# ES32F36xx register map
File version: 1.0
Registers are 32-bit, read-write, reset 0x0 unless marked. A register's access mark holds for its fields unless they carry their own. Offsets are from the block's base; [hi:lo] are bit positions; {n}, {i} and the like mark numbered series.

## ADC0
Base 0x40042000
Same registers: ADC1 0x40042400
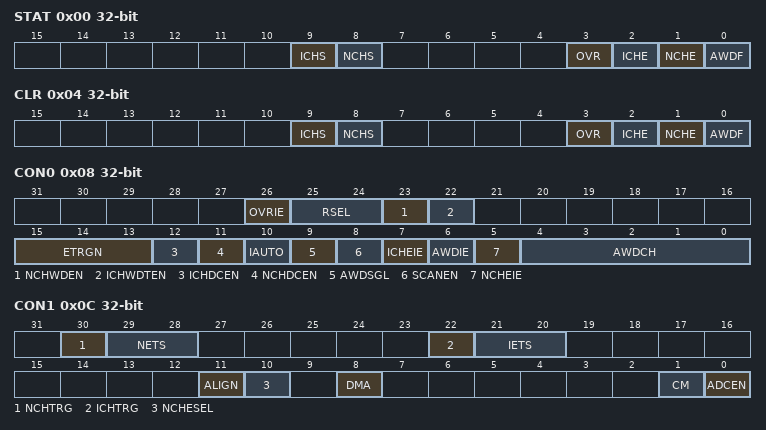
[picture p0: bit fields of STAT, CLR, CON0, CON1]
0x00 STAT read
  [9] ICHS, [8] NCHS, [3] OVR, [2] ICHE, [1] NCHE, [0] AWDF
0x04 CLR write1
  [9] ICHS, [8] NCHS, [3] OVR, [2] ICHE, [1] NCHE, [0] AWDF
0x08 CON0
  [26] OVRIE, [25:24] RSEL, [23] NCHWDEN, [22] ICHWDTEN, [15:13] ETRGN, [12] ICHDCEN, [11] NCHDCEN, [10] IAUTO, [9] AWDSGL, [8] SCANEN, [7] ICHEIE, [6] AWDIE, [5] NCHEIE, [4:0] AWDCH
0x0C CON1
  [30] NCHTRG write1, [29:28] NETS, [22] ICHTRG write1, [21:20] IETS, [11] ALIGN, [10] NCHESEL, [8] DMA, [1] CM, [0] ADCEN
0x10 SMPT1
  [31:0] CHT
0x14 SMPT2
  [31:0] CHT
0x18 SMPT3
  [15:0] CHT
{0x1C+4i} ICHOFF{i} (i=1..4)
  [11:0] IOFF
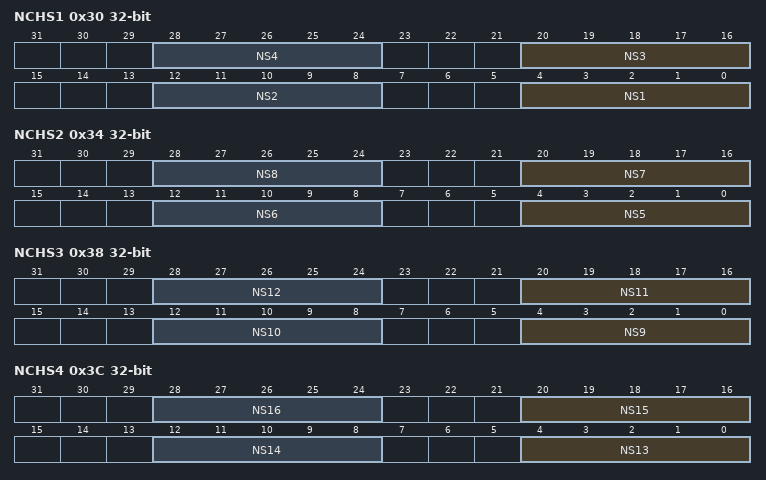
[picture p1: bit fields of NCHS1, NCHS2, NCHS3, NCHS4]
0x30 NCHS1
  [8n-4:8n-8] NS{n} (n=1..4)
0x34 NCHS2
  [8n-36:8n-40] NS{n} (n=5..8)
0x38 NCHS3
  [8n-68:8n-72] NS{n} (n=9..12)
0x3C NCHS4
  [8n-100:8n-104] NS{n} (n=13..16)
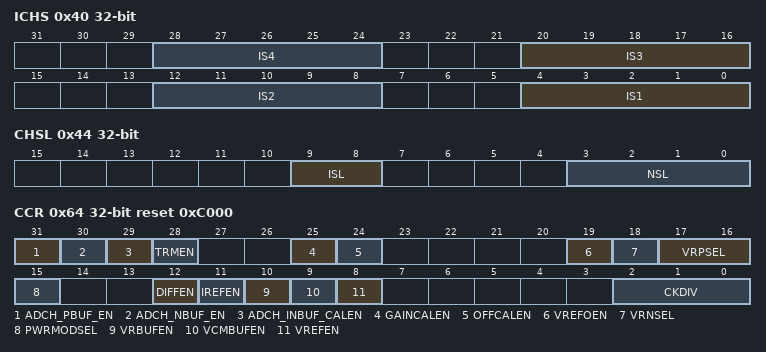
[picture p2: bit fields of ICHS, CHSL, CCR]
0x40 ICHS
  [8n-4:8n-8] IS{n} (n=1..4)
0x44 CHSL
  [9:8] ISL, [3:0] NSL
0x48 WDTH reset 0xFFF
  [11:0] HT
0x4C WDTL
  [11:0] LT
{0x4C+4i} ICHDR{i} read (i=1..4)
  [15:0] VAL
0x60 NCHDR read
  [15:0] VAL
0x64 CCR reset 0xC000
  [31] ADCH_PBUF_EN, [30] ADCH_NBUF_EN, [29] ADCH_INBUF_CALEN, [28] TRMEN, [25] GAINCALEN, [24] OFFCALEN, [19] VREFOEN, [18] VRNSEL, [17:16] VRPSEL, [15] PWRMODSEL, [12] DIFFEN, [11] IREFEN, [10] VRBUFEN, [9] VCMBUFEN, [8] VREFEN, [2:0] CKDIV

## ACMP0
Base 0x40043000
Same registers: ACMP1 0x40043400, ACMP2 0x40043800
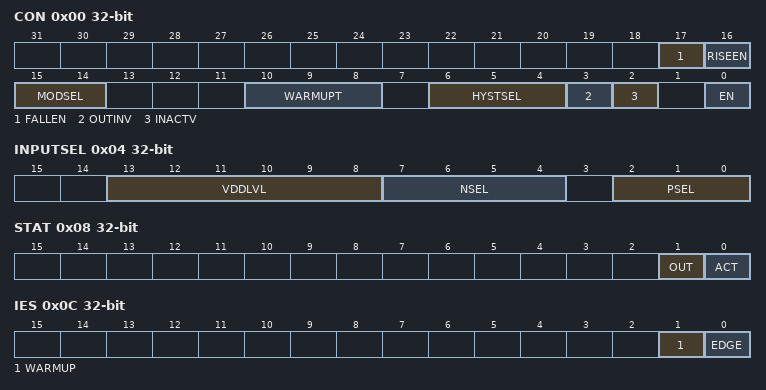
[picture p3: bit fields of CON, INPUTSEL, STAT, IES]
0x00 CON
  [17] FALLEN, [16] RISEEN, [15:14] MODSEL, [10:8] WARMUPT, [6:4] HYSTSEL, [3] OUTINV, [2] INACTV, [0] EN
0x04 INPUTSEL read
  [13:8] VDDLVL rw, [7:4] NSEL write, [2:0] PSEL
0x08 STAT read
  [1] OUT, [0] ACT
0x0C IES write1
  [1] WARMUP, [0] EDGE
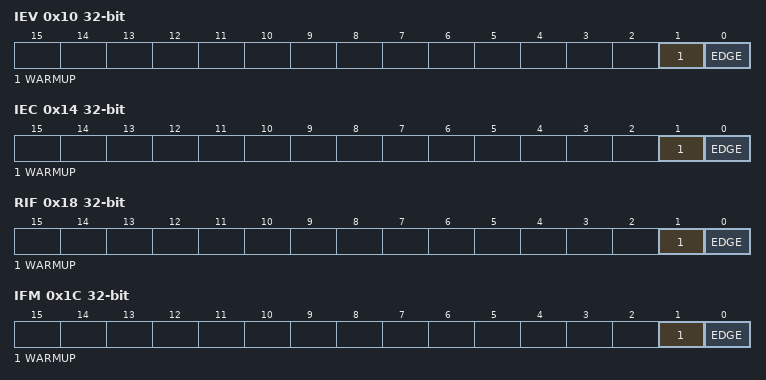
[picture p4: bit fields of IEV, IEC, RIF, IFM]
0x10 IEV read
  [1] WARMUP, [0] EDGE
0x14 IEC write1
  [1] WARMUP, [0] EDGE
0x18 RIF read
  [1] WARMUP, [0] EDGE
0x1C IFM read
  [1] WARMUP, [0] EDGE
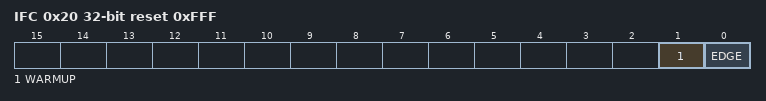
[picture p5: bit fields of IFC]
0x20 IFC write1 reset 0xFFF
  [1] WARMUP, [0] EDGE
0x24 PORT
  [0] PEN

## TSENSE
Base 0x40048800
0x00 WPR read reset 0x1
  [0] WP
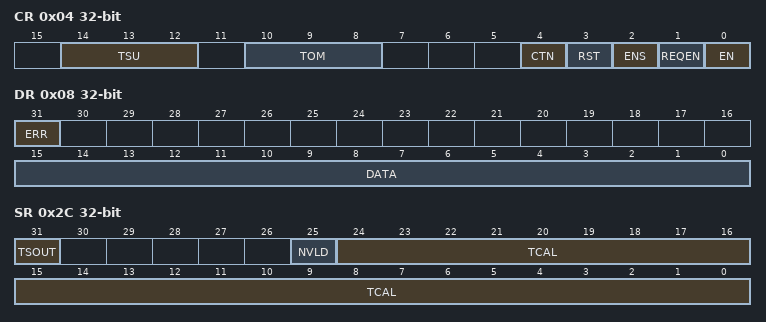
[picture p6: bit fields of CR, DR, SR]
0x04 CR
  [14:12] TSU, [10:8] TOM, [4] CTN, [3] RST write, [2] ENS read, [1] REQEN, [0] EN
0x08 DR read
  [31] ERR, [15:0] DATA
0x0C PSR
  [7:0] PRS
0x10 IE
  [0] TSENSE
0x14 IF read
  [0] TSENSE
0x18 IFCR
  [0] TSENSE
0x1C LTGR
  [20:0] LTG
0x20 HTGR
  [20:0] HTG
0x24 TBDR
  [15:0] TBD
0x28 TCALBDR
  [16:0] TCAL
0x2C SR read
  [31] TSOUT, [25] NVLD, [24:0] TCAL

## BKPC
Base 0x40048000
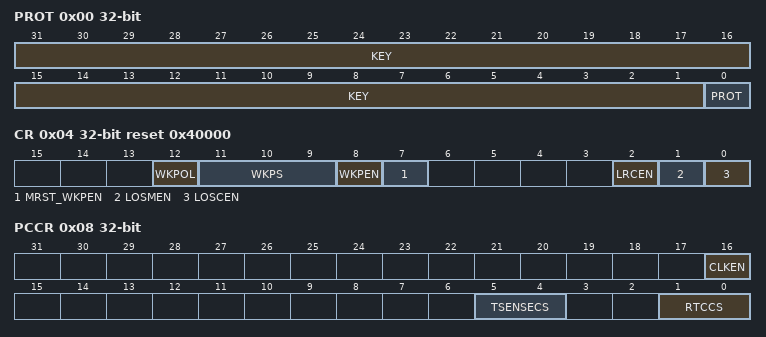
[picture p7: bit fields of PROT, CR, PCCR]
0x00 PROT read
  [31:1] KEY write, [0] PROT
0x04 CR reset 0x40000
  [12] WKPOL, [11:9] WKPS, [8] WKPEN, [7] MRST_WKPEN, [2] LRCEN, [1] LOSMEN, [0] LOSCEN
0x08 PCCR
  [16] CLKEN, [5:4] TSENSECS, [1:0] RTCCS
0x10 PDCR read
  [1] ISOLATE

## TRNG
Base 0x40085C00
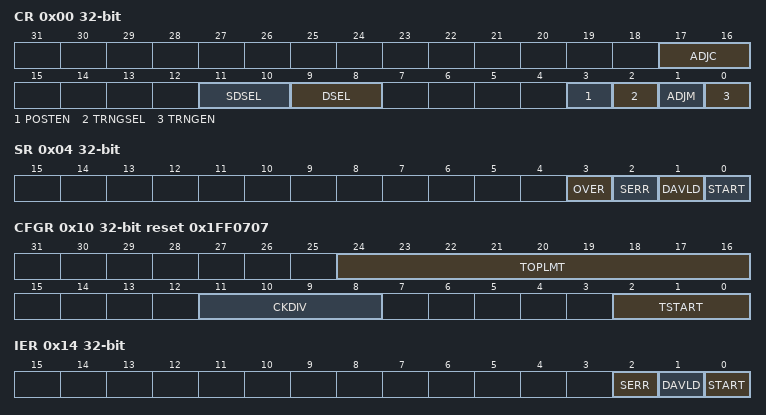
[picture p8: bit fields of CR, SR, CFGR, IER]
0x00 CR
  [17:16] ADJC, [11:10] SDSEL, [9:8] DSEL, [3] POSTEN, [2] TRNGSEL, [1] ADJM, [0] TRNGEN
0x04 SR read
  [3] OVER, [2] SERR, [1] DAVLD, [0] START
0x08 DR read
  [31:0] DATA
0x0C SEED
0x10 CFGR reset 0x1FF0707
  [24:16] TOPLMT, [11:8] CKDIV, [2:0] TSTART
0x14 IER
  [2] SERR, [1] DAVLD, [0] START
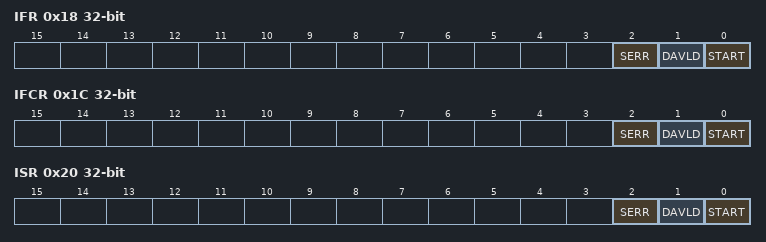
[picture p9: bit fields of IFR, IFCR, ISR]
0x18 IFR read
  [2] SERR, [1] DAVLD, [0] START
0x1C IFCR write1
  [2] SERR, [1] DAVLD, [0] START
0x20 ISR read
  [2] SERR, [1] DAVLD, [0] START

## WWDT
Base 0x40046000
0x00 LOAD reset 0x20000
0x04 VALUE read reset 0x3FFFFFFF
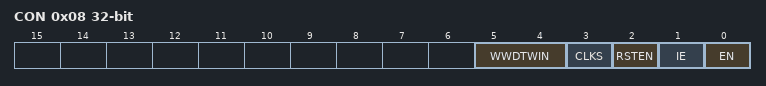
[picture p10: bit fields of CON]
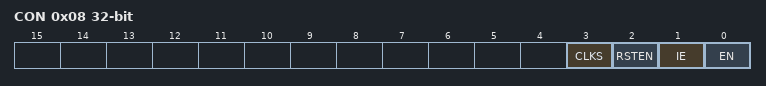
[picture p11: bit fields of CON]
0x08 CON
  [5:4] WWDTWIN, [3] CLKS, [2] RSTEN, [1] IE, [0] EN
0x0C INTCLR write
0x10 RIS read
  [0] WWDTIF
0x100 LOCK reset 0x1
  [0] LOCK

## IWDT
Base 0x40046400
0x00 LOAD reset 0x80000
0x04 VALUE read reset 0xFFFFFFFF
0x08 CON
  [3] CLKS, [2] RSTEN, [1] IE, [0] EN
0x0C INTCLR write
0x10 RIS read
  [0] WDTIF
0x100 LOCK reset 0x1
  [0] LOCK

## SYSCFG
Base 0x40080000
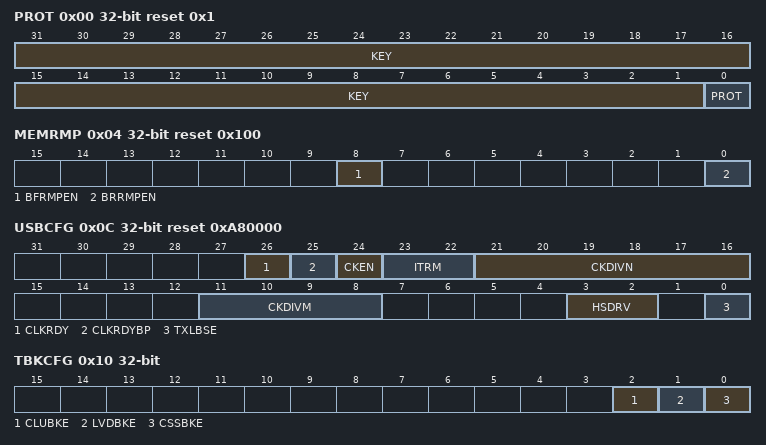
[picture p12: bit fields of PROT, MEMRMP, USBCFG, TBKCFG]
0x00 PROT read reset 0x1
  [31:1] KEY write, [0] PROT
0x04 MEMRMP reset 0x100
  [8] BFRMPEN, [0] BRRMPEN
0x0C USBCFG reset 0xA80000
  [26] CLKRDY read, [25] CLKRDYBP, [24] CKEN, [23:22] ITRM, [21:16] CKDIVN, [11:8] CKDIVM, [3:2] HSDRV, [0] TXLBSE
0x10 TBKCFG
  [2] CLUBKE, [1] LVDBKE, [0] CSSBKE
